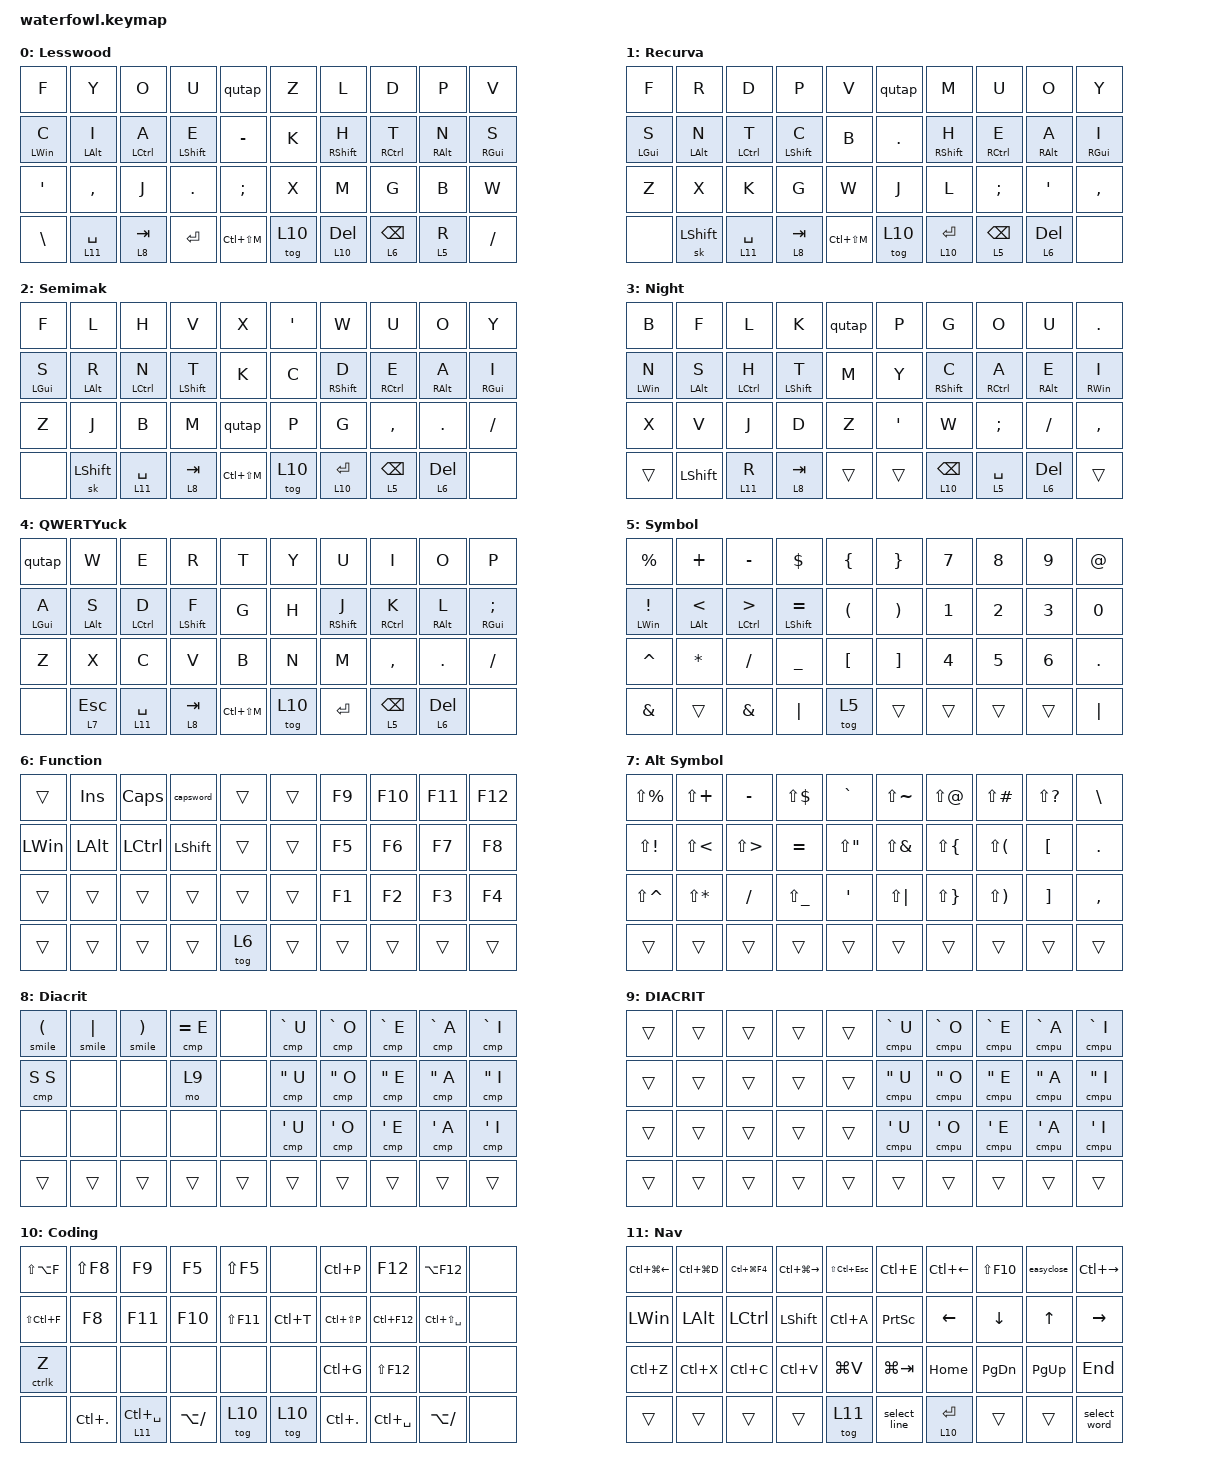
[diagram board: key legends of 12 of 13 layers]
/*
 * Copyright (c) 2022 The ZMK Contributors
 *
 * SPDX-License-Identifier: MIT
 */

#include "keypos.h"
#include <behaviors.dtsi>
#include <dt-bindings/zmk/bt.h>
#include <dt-bindings/zmk/keys.h>
#include <dt-bindings/zmk/outputs.h>

/* Global settings */

#define QUICK_TAP_MS 175
#define KEYS_L LT0 LT1 LT2 LT3 LT4 LM0 LM1 LM2 LM3 LM4 LB0 LB1 LB2 LB3 LB4  // left-hand keys
#define KEYS_R RT0 RT1 RT2 RT3 RT4 RM0 RM1 RM2 RM3 RM4 RB0 RB1 RB2 RB3 RB4  // right-hand keys
#define THUMBS LH4 LH3 LH2 LH1 LH0 RH0 RH1 RH2 LH3 LH4                                              // thumb keys

&sk { quick-release; };

/ {
    combos {
        compatible = "zmk,combos";

        Semicolon {
            bindings = <&kp SEMI>;
            key-positions = <27 28>;
            layers = <2 4>;
        };

        exclaim {
            bindings = <&kp EXCL>;
            key-positions = <26 27>;
        };

        dquot {
            bindings = <&kp DQT>;
            key-positions = <27 28>;
            layers = <1 5 3>;
        };

        question {
            bindings = <&kp QUESTION>;
            key-positions = <23 22>;
        };

        colon {
            bindings = <&kp COLON>;
            key-positions = <22 21>;
        };

        slash {
            bindings = <&kp SLASH>;
            key-positions = <20 21>;
        };

        backslash {
            bindings = <&kp BSLH>;
            key-positions = <29 28>;
        };

        capsword {
            bindings = <&capsword>;
            key-positions = <13 16>;
        };

        grave {
            bindings = <&kp GRAVE>;
            key-positions = <LT4 LT3 11 10>;
            layers = <1 2 4 11 0>;
        };

        // Symbol layer

        isnot {
            bindings = <&isnot>;
            key-positions = <10 13>;
            layers = <5>;
        };

        lambda {
            bindings = <&lambda>;
            key-positions = <LM1 LM2 13 12>;
            layers = <5>;
        };

        lambdablk {
            bindings = <&lambdablk>;
            key-positions = <LM1 LM2 LM3 13 12 11>;
            layers = <5>;
        };

        ZeroZero {
            bindings = <&zerozero>;
            key-positions = <RM3 RM4 19 18>;
            layers = <5>;
        };

        ZeroZeroZero {
            bindings = <&zerozerozero>;
            key-positions = <RM2 RM3 RM4 19 18 17>;
            layers = <5>;
        };

        // Diacrits

        u_caret {
            bindings = <&cmp CARET U>;
            key-positions = <RM0 RB0>;
            layers = <8>;
        };

        o_caret {
            bindings = <&cmp CARET O>;
            key-positions = <RM1 RB1>;
            layers = <8>;
        };

        e_caret {
            bindings = <&cmp CARET E>;
            key-positions = <RM2 RB2>;
            layers = <8>;
        };

        a_caret {
            bindings = <&cmp CARET A>;
            key-positions = <RM3 RB3>;
            layers = <8>;
        };

        i_caret {
            bindings = <&cmp CARET I>;
            key-positions = <RM4 RB4>;
            layers = <8>;
        };

        uu_caret {
            bindings = <&cmpu CARET U>;
            key-positions = <RM0 RB0>;
            layers = <9>;
        };

        ou_caret {
            bindings = <&cmpu CARET O>;
            key-positions = <RM1 RB1>;
            layers = <9>;
        };

        eu_caret {
            bindings = <&cmpu CARET E>;
            key-positions = <RM2 RB2>;
            layers = <9>;
        };

        au_caret {
            bindings = <&cmpu CARET A>;
            key-positions = <RM3 RB3>;
            layers = <9>;
        };

        iu_caret {
            bindings = <&cmpu CARET I>;
            key-positions = <RM4 RB4>;
            layers = <9>;
        };

        esc_combo {
            bindings = <&kp ESC>;
            key-positions = <31 32>;
            layers = <0>;
        };

        entercombo {
            bindings = <&kp ENTER>;
            key-positions = <19 29>;
            layers = <0 3>;
        };

        and_combo {
            bindings = <&kp AMPS>;
            key-positions = <6 16>;
            layers = <5>;
        };

        or_combo {
            bindings = <&kp PIPE>;
            key-positions = <7 17>;
            layers = <5>;
        };

        hash_combo {
            bindings = <&kp HASH>;
            key-positions = <3 13>;
            layers = <5>;
        };

        c_fij {
            bindings = <&m_fij>;
            key-positions = <0 1>;
            layers = <0>;
        };

        c_jo {
            bindings = <&m_jo>;
            key-positions = <1 2>;
            layers = <0>;
        };

        c_jou {
            bindings = <&m_jou>;
            key-positions = <1 2 3>;
            layers = <0>;
        };
    };

    behaviors {
        hml: hml {
            compatible = "zmk,behavior-hold-tap";
            #binding-cells = <2>;
            flavor = "balanced";
            tapping-term-ms = <280>;
            quick-tap-ms = <QUICK_TAP_MS>;                // repeat on tap-into-hold
            require-prior-idle-ms = <150>;
            bindings = <&kp>, <&kp>;

            hold-trigger-key-positions = <KEYS_R THUMBS 5 6 7 8 19 9 18 16 17 15 25 26 27 28 29 39 38 37 36 35>;
            hold-trigger-on-release;             // delay positional check until key-release
        };

        hmr: hmr {
            compatible = "zmk,behavior-hold-tap";
            #binding-cells = <2>;
            flavor = "balanced";
            tapping-term-ms = <280>;
            quick-tap-ms = <QUICK_TAP_MS>;                // repeat on tap-into-hold
            require-prior-idle-ms = <150>;
            bindings = <&kp>, <&kp>;

            hold-trigger-key-positions = <KEYS_L THUMBS 0 1 2 3 4 10 11 12 13 14 20 21 22 23 24 30 31 32 33 34>;
            hold-trigger-on-release;             // delay positional check until key-release
        };

        capsword: capsword {
            compatible = "zmk,behavior-caps-word";
            #binding-cells = <0>;
            continue-list = <UNDERSCORE MINUS>;
        };

        easynew: easynew {
            compatible = "zmk,behavior-mod-morph";
            bindings = <&kp LC(N)>, <&kp N>;

            #binding-cells = <0>;
            mods = <(MOD_LALT)>;
        };

        easyclose: easyclose {
            compatible = "zmk,behavior-mod-morph";
            bindings = <&kp LC(F4)>, <&kp F4>;

            #binding-cells = <0>;
            mods = <(MOD_LALT)>;
        };

        qutap: qutap {
            compatible = "zmk,behavior-tap-dance";
            #binding-cells = <0>;
            bindings = <&qumacro>, <&kp Q>;

            tapping-term-ms = <200>;
        };

        extend_line: extend_line {
            compatible = "zmk,behavior-mod-morph";
            bindings = <&extend_line_right>, <&extend_line_left>;

            #binding-cells = <0>;
            mods = <(MOD_LSFT|MOD_RSFT)>;
        };

        select_line: select_line {
            compatible = "zmk,behavior-mod-morph";
            bindings = <&select_line_right>, <&select_line_left>;

            #binding-cells = <0>;
            mods = <(MOD_LSFT|MOD_RSFT)>;
        };

        select_word: select_word {
            compatible = "zmk,behavior-mod-morph";
            bindings = <&select_word_right>, <&select_word_left>;

            #binding-cells = <0>;
            mods = <(MOD_LSFT|MOD_RSFT)>;
        };

        extend_word: extend_word {
            compatible = "zmk,behavior-mod-morph";
            bindings = <&extend_word_right>, <&extend_word_left>;

            #binding-cells = <0>;
            mods = <(MOD_LSFT|MOD_RSFT)>;
        };

        rotate_extend_word: rotate_extend_word {
            compatible = "zmk,behavior-sensor-rotate";
            #sensor-binding-cells = <0>;
            bindings = <&extend_word_left>, <&extend_word_right>;
        };

        rotate_extend_line: rotate_extend_line {
            compatible = "zmk,behavior-sensor-rotate";
            #sensor-binding-cells = <0>;
            bindings = <&extend_line_left>, <&extend_line_right>;
        };
    };

    macros {
        smile: smile {
            compatible = "zmk,behavior-macro-one-param";
            #binding-cells = <1>;
            bindings = <&kp COLON &kp MINUS &macro_param_1to1 &kp MACRO_PLACEHOLDER>;
        };

        ctrlk: ctrlk {
            compatible = "zmk,behavior-macro-one-param";
            #binding-cells = <1>;
            bindings = <&kp LC(K) &macro_param_1to1 &kp MACRO_PLACEHOLDER>;
        };

        cmp: comp {
            compatible = "zmk,behavior-macro-two-param";
            #binding-cells = <2>;
            bindings = <&kp RALT &macro_param_1to1 &kp MACRO_PLACEHOLDER &macro_param_2to1 &kp MACRO_PLACEHOLDER>;
        };

        cmpu: compup {
            compatible = "zmk,behavior-macro-two-param";
            #binding-cells = <2>;
            bindings =
                <&kp RALT &macro_param_1to1 &kp MACRO_PLACEHOLDER>,
                <&macro_press>,
                <&kp LSHFT>,
                <&macro_tap>,
                <&macro_param_2to1 &kp MACRO_PLACEHOLDER>,
                <&macro_release>,
                <&kp LSHFT>;

        };

        isnot: isnot {
            compatible = "zmk,behavior-macro";
            #binding-cells = <0>;
            bindings = <&kp I &kp S &kp SPACE &kp N &kp O &kp T &kp SPACE>;
            wait-ms = <1>;
            tap-ms = <1>;
        };

        lambda: lambda {
            compatible = "zmk,behavior-macro";
            #binding-cells = <0>;
            bindings = <&kp SPACE &kp EQUAL &kp GT &kp SPACE>;
            wait-ms = <1>;
            tap-ms = <1>;
        };

        lambdablk: lambdablk {
            compatible = "zmk,behavior-macro";
            #binding-cells = <0>;
            bindings = <&lambda &kp LBRC &kp ENTER>;
            wait-ms = <1>;
            tap-ms = <1>;
        };

        zerozero: zerozero {
            compatible = "zmk,behavior-macro";
            #binding-cells = <0>;
            bindings = <&kp N0 &kp N0>;
            wait-ms = <1>;
            tap-ms = <1>;
        };

        zerozerozero: zerozerozero {
            compatible = "zmk,behavior-macro";
            #binding-cells = <0>;
            bindings = <&kp N0 &kp N0 &kp N0>;
            wait-ms = <1>;
            tap-ms = <1>;
        };

        qumacro: QuMacro {
            compatible = "zmk,behavior-macro";
            #binding-cells = <0>;
            bindings =
                <&kp Q>,
                <&macro_release>,
                <&kp LSHFT &kp RSHFT>,
                <&macro_tap>,
                <&kp U>;

            wait-ms = <1>;
            tap-ms = <1>;
        };

        select_word_right: select_word_right {
            compatible = "zmk,behavior-macro";
            #binding-cells = <0>;
            bindings = <&kp RIGHT &kp LA(RIGHT) &kp LA(LEFT) &kp LS(LA(RIGHT))>;
            wait-ms = <1>;
            tap-ms = <1>;
        };

        select_word_left: select_word_left {
            compatible = "zmk,behavior-macro";
            #binding-cells = <0>;
            bindings = <&kp LEFT &kp LA(LEFT) &kp LA(RIGHT) &kp LS(LA(LEFT))>;
            wait-ms = <1>;
            tap-ms = <1>;
        };

        extend_word_right: extend_word_right {
            compatible = "zmk,behavior-macro";
            #binding-cells = <0>;
            bindings = <&kp LS(LA(RIGHT))>;
            wait-ms = <1>;
            tap-ms = <1>;
        };

        extend_word_left: extend_word_left {
            compatible = "zmk,behavior-macro";
            #binding-cells = <0>;
            bindings = <&kp LS(LA(LEFT))>;
            wait-ms = <1>;
            tap-ms = <1>;
        };

        select_line_right: select_line_right {
            compatible = "zmk,behavior-macro";
            #binding-cells = <0>;
            bindings = <&kp HOME &kp LS(END)>;
            wait-ms = <1>;
            tap-ms = <1>;
        };

        select_line_left: select_line_left {
            compatible = "zmk,behavior-macro";
            #binding-cells = <0>;
            bindings = <&kp END &kp LS(HOME)>;
            wait-ms = <1>;
            tap-ms = <1>;
        };

        extend_line_right: extend_line_right {
            compatible = "zmk,behavior-macro";
            #binding-cells = <0>;
            bindings = <&kp LS(DOWN) &kp LS(END)>;
            wait-ms = <1>;
            tap-ms = <1>;
        };

        extend_line_left: extend_line_left {
            compatible = "zmk,behavior-macro";
            #binding-cells = <0>;
            bindings = <&kp LS(UP) &kp LS(HOME)>;
            wait-ms = <1>;
            tap-ms = <1>;
        };

        m_fij: m_fij {
            compatible = "zmk,behavior-macro";
            #binding-cells = <0>;
            bindings =
                <&kp F>,
                <&macro_release>,
                <&kp LSHFT &kp RSHFT>,
                <&macro_tap>,
                <&kp I &kp J>;

            wait-ms = <1>;
            tap-ms = <1>;
        };

        m_jo: m_jo {
            compatible = "zmk,behavior-macro";
            #binding-cells = <0>;
            bindings =
                <&kp J>,
                <&macro_release>,
                <&kp LSHFT &kp RSHFT>,
                <&macro_tap>,
                <&kp O>;

            wait-ms = <1>;
            tap-ms = <1>;
        };

        m_jou: m_jou {
            compatible = "zmk,behavior-macro";
            #binding-cells = <0>;
            bindings =
                <&kp J>,
                <&macro_release>,
                <&kp LSHFT &kp RSHFT>,
                <&macro_tap>,
                <&kp O &kp U>;

            wait-ms = <1>;
            tap-ms = <1>;
        };
    };

    keymap {
        compatible = "zmk,keymap";

        Lesswood_layer {
            bindings = <
&kp F          &kp Y         &kp O         &kp U          &qutap           &kp Z    &kp L          &kp D            &kp P        &kp V
&hml LWIN C    &hml LALT I   &hml LCTRL A  &hml LSHIFT E  &kp MINUS        &kp K    &hmr RSHIFT H  &hmr RCTRL T     &hmr RALT N  &hmr RGUI S
&kp APOS       &kp COMMA     &kp J         &kp DOT        &kp SEMI         &kp X    &kp M          &kp G            &kp B        &kp W
&kp BACKSLASH  &lt 11 SPACE  &lt 8 TAB     &kp ENTER      &kp LC(LS(M))    &tog 10  &lt 10 DELETE  &lt 6 BACKSPACE  &lt 5 R      &kp SLASH
            >;

            sensor-bindings =
                <&inc_dec_kp UP DOWN>,
                <&inc_dec_kp C_VOL_DN C_VOL_UP>,
                <&inc_dec_kp PAGE_UP PAGE_DOWN>,
                <&inc_dec_kp LEFT RIGHT>;

            display-name = "Lesswood";
        };

        recurva_layer {
            /* Recurva
 *
 * ,----------------------------------.                      ,----------------------------------.
 * |   F  |   R  |   D  |   P  |   V  |                      |   Q  |   M  |   U  |   O  |   Y  |
 * |------+------+------+------+------|                      |------+------+------+------+------|
 * |   S  |   N  |   T  |   C  |   B  |                      |   .  |   H  |   E  |   A  |   I  |
 * |------+------+------+------+------|  ,-----.    ,-----.  |------+------+------+------+------|
 * |   Z  |   X  |   K  |   G  |   W  |  |  2  |    |  3  |  |   J  |   L  |   ;  |   '  |   ,  |
 * `----------------------------------'  `-----'    `-----'  `----------------------------------'
 *          ,-----.   ,--------------------.            ,--------------------.   ,-----.
 *          |  1  |   | DEL | SPACE | TAB  |            |  ESC  | BS | ENTER |   |  4  |
 *          `-----'   `--------------------'            `--------------------'   `-----'
 */

            bindings = <
&kp F        &kp R        &kp D         &kp P         &kp V            &qutap   &kp M         &kp U            &kp O        &kp Y
&hml LGUI S  &hml LALT N  &hml LCTRL T  &hml LSHFT C  &kp B            &kp DOT  &hmr RSHFT H  &hmr RCTRL E     &hmr RALT A  &hmr RGUI I
&kp Z        &kp X        &kp K         &kp G         &kp W            &kp J    &kp L         &kp SEMI         &kp SQT      &kp COMMA
&none        &sk LSHFT    &lt 11 SPACE  &lt 8 TAB     &kp LC(LS(M))    &tog 10  &lt 10 ENTER  &lt 5 BACKSPACE  &lt 6 DEL    &none
            >;

            sensor-bindings =
                <&inc_dec_kp UP DOWN>,
                <&inc_dec_kp C_VOL_DN C_VOL_UP>,
                <&inc_dec_kp PAGE_UP PAGE_DOWN>,
                <&inc_dec_kp LEFT RIGHT>;

            display-name = "Recurva";
        };

        semimak_layer {
            /* Semimak JQZ
 *
 * ,----------------------------------.                      ,----------------------------------.
 * |   F  |   L  |   H  |   V  |   X  |                      |   '  |   W  |   U  |   O  |   Y  |
 * |------+------+------+------+------|                      |------+------+------+------+------|
 * |   S  |   R  |   N  |   T  |   K  |                      |   C  |   D  |   E  |   A  |   I  |
 * |------+------+------+------+------|  ,-----.    ,-----.  |------+------+------+------+------|
 * |   Z  |   J  |   B  |   M  |   Q  |  |  2  |    |  3  |  |   P  |   G  |   ,  |   .  |   /  |
 * `----------------------------------'  `-----'    `-----'  `----------------------------------'
 *          ,-----.   ,--------------------.            ,--------------------.   ,-----.
 *          |  1  |   | DEL | SPACE | TAB  |            |  ESC  | BS | ENTER |   |  4  |
 *          `-----'   `--------------------'            `--------------------'   `-----'
 */

            bindings = <
&kp F        &kp L        &kp H         &kp V         &kp X            &kp SQT  &kp W         &kp U            &kp O        &kp Y
&hml LGUI S  &hml LALT R  &hml LCTRL N  &hml LSHFT T  &kp K            &kp C    &hmr RSHFT D  &hmr RCTRL E     &hmr RALT A  &hmr RGUI I
&kp Z        &kp J        &kp B         &kp M         &qutap           &kp P    &kp G         &kp COMMA        &kp DOT      &kp FSLH
&none        &sk LSHFT    &lt 11 SPACE  &lt 8 TAB     &kp LC(LS(M))    &tog 10  &lt 10 ENTER  &lt 5 BACKSPACE  &lt 6 DEL    &none
            >;

            sensor-bindings = <
                &inc_dec_kp UP DOWN
                &inc_dec_kp C_VOL_DN C_VOL_UP
                &inc_dec_kp PAGE_UP PAGE_DOWN
                &inc_dec_kp LEFT RIGHT
            >;

            display-name = "Semimak";
        };

        Night {
            bindings = <
&kp B            &kp F            &kp L         &kp K         &qutap    &kp P    &kp G             &kp O         &kp U         &kp DOT
&hml LEFT_WIN N  &hml LEFT_ALT S  &hml LCTRL H  &hml LSHFT T  &kp M     &kp Y    &hmr RSHFT C      &hmr RCTRL A  &hmr RALT E   &hmr RWIN I
&kp X            &kp V            &kp J         &kp D         &kp Z     &kp SQT  &kp W             &kp SEMI      &kp FSLH      &kp COMMA
&trans           &kp LSHIFT       &lt 11 R      &lt 8 TAB     &trans    &trans   &lt 10 BACKSPACE  &lt 5 SPACE   &lt 6 DELETE  &trans
            >;

            sensor-bindings =
                <&inc_dec_kp UP DOWN>,
                <&inc_dec_kp C_VOL_DN C_VOL_UP>,
                <&inc_dec_kp PAGE_UP PAGE_DOWN>,
                <&inc_dec_kp LEFT RIGHT>;

            display-name = "Night";
        };

        qwerty_layer {
            /* QWERTY
 *
 * ,----------------------------------.                      ,----------------------------------.
 * |   Q  |   W  |   E  |   R  |   T  |                      |   Y  |   U  |   I  |   O  |   P  |
 * |------+------+------+------+------|                      |------+------+------+------+------|
 * |   A  |   S  |   D  |   F  |   G  |                      |   H  |   J  |   K  |   L  |   ;  |
 * |------+------+------+------+------|  ,-----.    ,-----.  |------+------+------+------+------|
 * |   Z  |   X  |   C  |   V  |   B  |  |  2  |    |  3  |  |   N  |   M  |   ,  |   .  |   /  |
 * `----------------------------------'  `-----'    `-----'  `----------------------------------'
 *          ,-----.   ,--------------------.            ,--------------------.   ,-----.
 *          |  1  |   | DEL | SPACE | TAB  |            |  ESC  | BS | ENTER |   |  4  |
 *          `-----'   `--------------------'            `--------------------'   `-----'
 */

            bindings = <
&qutap       &kp W        &kp E         &kp R         &kp T            &kp Y    &kp U         &kp I            &kp O        &kp P
&hml LGUI A  &hml LALT S  &hml LCTRL D  &hml LSHFT F  &kp G            &kp H    &hmr RSHFT J  &hmr RCTRL K     &hmr RALT L  &hmr RGUI SEMI
&kp Z        &kp X        &kp C         &kp V         &kp B            &kp N    &kp M         &kp COMMA        &kp DOT      &kp FSLH
&none        &lt 7 ESC    &lt 11 SPACE  &lt 8 TAB     &kp LC(LS(M))    &tog 10  &kp ENTER     &lt 5 BACKSPACE  &lt 6 DEL    &none
            >;

            sensor-bindings = <
                &inc_dec_kp UP DOWN
                &inc_dec_kp C_VOL_DN C_VOL_UP
                &inc_dec_kp PAGE_UP PAGE_DOWN
                &inc_dec_kp LEFT RIGHT
            >;

            display-name = "QWERTYuck";
        };

        symbol_layer {
            /* SYM
 *
 * ,----------------------------------.                      ,----------------------------------.
 * |   %  |   @  |   [  |   ]  |   \  |                      |      |      |   ^  |      |      |
 * |------+------+------+------+------|                      |------+------+------+------+------|
 * |   #  |   !  |   (  |   )  |   |  |                      |   _  |   '  |   "  |   ~  |   `  |
 * |------+------+------+------+------|  ,-----.    ,-----.  |------+------+------+------+------|
 * |   $  |      |   {  |   }  |   &  |  |  2  |    |  3  |  |      |      |      |      |      |
 * `----------------------------------'  `-----'    `-----'  `----------------------------------'
 *          ,-----.   ,--------------------.            ,--------------------.   ,-----.
 *          |  1  |   | DEL | SPACE | TAB  |            |  ESC  | BS | ENTER |   |  4  |
 *          `-----'   `--------------------'            `--------------------'   `-----'
 */

            bindings = <
&kp PRCNT       &kp PLUS      &kp MINUS      &kp DOLLAR        &kp LBRC    &kp RBRC  &kp N7  &kp N8  &kp N9  &kp AT
&hml LWIN EXCL  &hml LALT LT  &hml LCTRL GT  &hml LSHFT EQUAL  &kp LPAR    &kp RPAR  &kp N1  &kp N2  &kp N3  &kp N0
&kp CARET       &kp ASTRK     &kp SLASH      &kp UNDER         &kp LBKT    &kp RBKT  &kp N4  &kp N5  &kp N6  &kp DOT
&kp AMPS        &trans        &kp AMPS       &kp PIPE          &tog 5      &trans    &trans  &trans  &trans  &kp PIPE
            >;

            sensor-bindings =
                <&inc_dec_kp UP DOWN>,
                <&inc_dec_kp AMPS PIPE>,
                <&inc_dec_kp PAGE_UP PAGE_DOWN>,
                <&inc_dec_kp LEFT RIGHT>;

            display-name = "Symbol";
        };

        function_layer {
            /* FUNC
 *
 * ,----------------------------------.                      ,----------------------------------.
 * |      |      | BTCLR|      | Reset|                      | Reset|  F7  |  F8  |  F9  |  F11 |
 * |------+------+------+------+------|                      |------+------+------+------+------|
 * |  BT0 |  BT1 |  BT2 |  BT3 |  BT4 |                      |      |  F4  |  F5  |  F6  |  F12 |
 * |------+------+------+------+------|  ,-----.    ,-----.  |------+------+------+------+------|
 * |      |      |      |      |      |  |  2  |    |  3  |  |  F10 |  F1  |  F2  |  F3  |  F13 |
 * `----------------------------------'  `-----'    `-----'  `----------------------------------'
 *          ,-----.   ,--------------------.            ,--------------------.   ,-----.
 *          |  1  |   | DEL | SPACE | TAB  |            |  ESC  | BS | ENTER |   |  4  |
 *          `-----'   `--------------------'            `--------------------'   `-----'
 */

            bindings = <
&trans    &kp INS   &kp CLCK   &capsword  &trans    &trans  &kp F9  &kp F10  &kp F11  &kp F12
&kp LWIN  &kp LALT  &kp LCTRL  &kp LSHFT  &trans    &trans  &kp F5  &kp F6   &kp F7   &kp F8
&trans    &trans    &trans     &trans     &trans    &trans  &kp F1  &kp F2   &kp F3   &kp F4
&trans    &trans    &trans     &trans     &tog 6    &trans  &trans  &trans   &trans   &trans
            >;

            sensor-bindings = <
                &inc_dec_kp UP DOWN
                &inc_dec_kp C_VOL_DN C_VOL_UP
                &inc_dec_kp PAGE_UP PAGE_DOWN
                &inc_dec_kp LEFT RIGHT
            >;

            display-name = "Function";
        };

        altsym_layer {
            bindings = <
&kp LS(PRCNT)  &kp LS(PLUS)  &kp MINUS   &kp LS(DLLR)   &kp GRAVE      &kp LS(TILDE)  &kp LS(AT)    &kp LS(POUND)  &kp LS(QMARK)  &kp BSLH
&kp LS(EXCL)   &kp LS(LT)    &kp LS(GT)  &kp EQUAL      &kp LS(DQT)    &kp LS(AMPS)   &kp LS(LBRC)  &kp LS(LPAR)   &kp LBKT       &kp DOT
&kp LS(CARET)  &kp LS(STAR)  &kp FSLH    &kp LS(UNDER)  &kp SQT        &kp LS(PIPE)   &kp LS(RBRC)  &kp LS(RPAR)   &kp RBKT       &kp COMMA
&trans         &trans        &trans      &trans         &trans         &trans         &trans        &trans         &trans         &trans
            >;

            display-name = "Alt Symbol";
        };

        Diacrit_layer {
            bindings = <
&smile LPAR  &smile PIPE  &smile RPAR  &cmp EQUAL E  &none     &cmp GRAVE U  &cmp GRAVE O  &cmp GRAVE E  &cmp GRAVE A  &cmp GRAVE I
&cmp S S     &none        &none        &mo 9         &none     &cmp DQT U    &cmp DQT O    &cmp DQT E    &cmp DQT A    &cmp DQT I
&none        &none        &none        &none         &none     &cmp SQT U    &cmp SQT O    &cmp SQT E    &cmp SQT A    &cmp SQT I
&trans       &trans       &trans       &trans        &trans    &trans        &trans        &trans        &trans        &trans
            >;

            display-name = "Diacrit";
        };

        Diacrit_Upper_layer {
            bindings = <
&trans  &trans  &trans  &trans  &trans    &cmpu GRAVE U  &cmpu GRAVE O  &cmpu GRAVE E  &cmpu GRAVE A  &cmpu GRAVE I
&trans  &trans  &trans  &trans  &trans    &cmpu DQT U    &cmpu DQT O    &cmpu DQT E    &cmpu DQT A    &cmpu DQT I
&trans  &trans  &trans  &trans  &trans    &cmpu SQT U    &cmpu SQT O    &cmpu SQT E    &cmpu SQT A    &cmpu SQT I
&trans  &trans  &trans  &trans  &trans    &trans         &trans         &trans         &trans         &trans
            >;

            display-name = "DIACRIT";
        };

        Coding {
            /* Coding
 *
 * ,------------------------------------------------------.    ,------------------------------------------------------.
 * |FORMAT    |PREV ERROR|SET BREAKP|RUN DEBUG |STOP DEBUG|    |          |QUICK OPEN|GOTO DEF  |PEEK DEF  |          |
 * |----------+----------+----------+----------+----------|    |----------+----------+----------+----------+----------|
 * |FIND FILES|NEXT ERROR|STEP INTO |STEP OVER |STEP OUT  |    |SHW SYMBLS|COMMAND PL|GOTO IMPLM|SHOW PARAM|          |
 * |----------+----------+----------+----------+----------|    |----------+----------+----------+----------+----------|
 * |ZEN       |          |          |          |          |    |          |GOTO LINE |SHOW REFS |          |          |
 * '------------------------------------------------------'    '------------------------------------------------------'
 *                     ,-----.   ,------------------------.            ,--------------------.   ,-----.
 *                     |  1  |   | DEL | SPACE | COPILOT  |            |  ESC  | BS | ENTER |   |  4  |
 *                     `-----'   `------------------------'            `--------------------'   `-----'
 */

            bindings = <
&kp LS(LA(F))  &kp LS(F8)   &kp F9            &kp F5         &kp LS(F5)     &none      &kp LC(P)      &kp F12        &kp LA(F12)        &none
&kp LS(LC(F))  &kp F8       &kp F11           &kp F10        &kp LS(F11)    &kp LC(T)  &kp LC(LS(P))  &kp LC(F12)    &kp LC(LS(SPACE))  &none
&ctrlk Z       &none        &none             &none          &none          &none      &kp LC(G)      &kp LS(F12)    &none              &none
&none          &kp LC(DOT)  &lt 11 LC(SPACE)  &kp LA(SLASH)  &tog 10        &tog 10    &kp LC(DOT)    &kp LC(SPACE)  &kp LA(SLASH)      &none
            >;

            sensor-bindings =
                <&inc_dec_kp UP DOWN>,
                <&inc_dec_kp C_VOL_DN C_VOL_UP>,
                <&inc_dec_kp PAGE_UP PAGE_DOWN>,
                <&inc_dec_kp LEFT RIGHT>;

            display-name = "Coding";
        };

        nav_layer {
            /* NAVNUM
 *
 * ,----------------------------------.                      ,----------------------------------.
 * |      | PgUp |  UP  | PgDn |      |                      |   /  |   7  |   8  |   9  |   -  |
 * |------+------+------+------+------|                      |------+------+------+------+------|
 * | Home | Left | Down | Right| End  |                      |   =  |   4  |   5  |   6  |   +  |
 * |------+------+------+------+------|  ,-----.    ,-----.  |------+------+------+------+------|
 * |      |      |  INS |      |      |  |  2  |    |  3  |  |   0  |   1  |   2  |   3  |   *  |
 * `----------------------------------'  `-----'    `-----'  `----------------------------------'
 *          ,-----.   ,--------------------.            ,--------------------.   ,-----.
 *          |  1  |   | DEL | SPACE | MO(3)|            |  ESC  | BS | ENTER |   |  4  |
 *          `-----'   `--------------------'            `--------------------'   `-----'
 */

            bindings = <
&kp LC(LG(LEFT))  &kp LC(LG(D))  &kp LC(LG(F4))  &kp LC(LG(RIGHT))  &kp LS(LC(ESC))    &kp LC(E)     &kp LC(LEFT)  &kp LS(F10)  &easyclose  &kp LC(RIGHT)
&kp LWIN          &kp LALT       &kp LCTRL       &kp LSHFT          &kp LC(A)          &kp PSCRN     &kp LEFT      &kp DOWN     &kp UP      &kp RIGHT
&kp LC(Z)         &kp LC(X)      &kp LC(C)       &kp LC(V)          &kp LG(V)          &kp LG(TAB)   &kp HOME      &kp PG_DN    &kp PG_UP   &kp END
&trans            &trans         &trans          &trans             &tog 11            &select_line  &lt 10 ENTER  &trans       &trans      &select_word
            >;

            sensor-bindings = <
                &inc_dec_kp PAGE_DOWN PAGE_UP
                &inc_dec_kp C_VOL_DN C_VOL_UP
                &rotate_extend_line
                &rotate_extend_word
            >;

            display-name = "Nav";
        };

        adjust_layer {
            bindings = <
&bootloader   &sys_reset    &bt BT_PRV    &bt BT_NXT    &bt BT_CLR_ALL    &bootloader  &sys_reset  &none  &none  &none
&bt BT_SEL 0  &bt BT_SEL 1  &bt BT_SEL 2  &bt BT_SEL 3  &bt BT_SEL 4      &to 0        &to 1       &to 2  &to 3  &to 4
&none         &none         &none         &out OUT_TOG  &bt BT_CLR_ALL    &none        &none       &none  &none  &none
&none         &none         &none         &none         &none             &none        &none       &none  &none  &none
            >;

            display-name = "Adjust";
        };
    };

    conditional_layers {
        compatible = "zmk,conditional-layers";

        adjustlayer {
            if-layers = <11 5>;
            then-layer = <12>;
        };
    };
};
